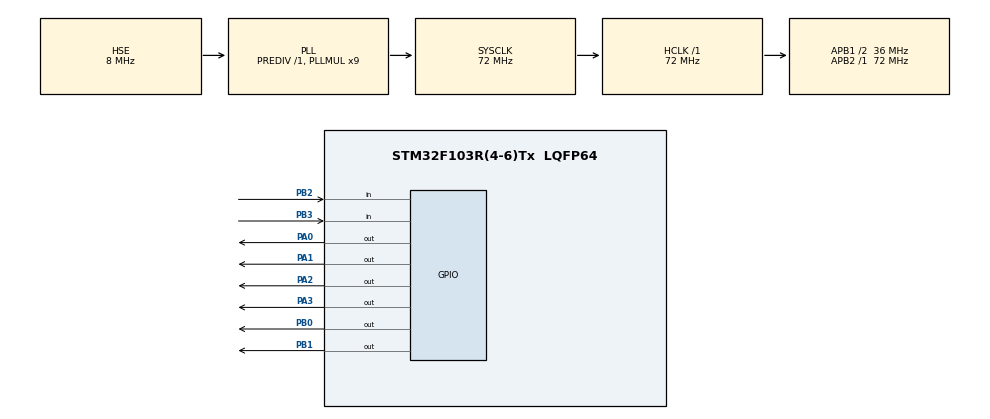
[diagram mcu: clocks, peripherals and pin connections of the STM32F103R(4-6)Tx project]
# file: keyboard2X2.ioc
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Mcu.Family=STM32F1
Mcu.Name=STM32F103R(4-6)Tx
Mcu.Package=LQFP64
NVIC.PriorityGroup=NVIC_PRIORITYGROUP_4
PA0-WKUP.Signal=GPIO_Output
PA1.Signal=GPIO_Output
PA2.Signal=GPIO_Output
PA3.Signal=GPIO_Output
PB0.Signal=GPIO_Output
PB1.Signal=GPIO_Output
PB2.GPIO_PuPd=GPIO_NOPULL
PB2.Signal=GPIO_Input
PB3.GPIO_PuPd=GPIO_NOPULL
PB3.Signal=GPIO_Input
PD0-OSC_IN.Mode=HSE-External-Oscillator
PD0-OSC_IN.Signal=RCC_OSC_IN
PD1-OSC_OUT.Mode=HSE-External-Oscillator
PD1-OSC_OUT.Signal=RCC_OSC_OUT
ProjectManager.HeapSize=0x200
ProjectManager.StackSize=0x400
ProjectManager.TargetToolchain=MDK-ARM V5
RCC.AHBFreq_Value=72000000
RCC.APB1CLKDivider=RCC_HCLK_DIV2
RCC.APB1Freq_Value=36000000
RCC.APB1TimFreq_Value=72000000
RCC.APB2Freq_Value=72000000
RCC.APB2TimFreq_Value=72000000
RCC.HCLKFreq_Value=72000000
RCC.PLLMUL=RCC_PLL_MUL9
RCC.PLLSourceVirtual=RCC_PLLSOURCE_HSE
RCC.SYSCLKFreq_VALUE=72000000
RCC.SYSCLKSource=RCC_SYSCLKSOURCE_PLLCLK
RCC.USBFreq_Value=72000000
VP_SYS_VS_ND.Mode=No_Debug
board=custom

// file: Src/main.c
/* USER CODE BEGIN Header */
/**
  ******************************************************************************
  * @file           : main.c
  * @brief          : Main program body
  ******************************************************************************
  * @attention
  *
  * <h2><center>&copy; Copyright (c) 2021 STMicroelectronics.
  * All rights reserved.</center></h2>
  *
  * This software component is licensed by ST under BSD 3-Clause license,
  * the "License"; You may not use this file except in compliance with the
  * License. You may obtain a copy of the License at:
  *                        opensource.org/licenses/BSD-3-Clause
  *
  ******************************************************************************
  */
/*
@file	《嵌入式微控制器原理及设计》书籍（作者:毕盛等 Email:picy@scut.edu.cn  电子工业出版社）配套实例ch5.6
*/
/* USER CODE END Header */

#include "main.h"
#include "gpio.h"

void SystemClock_Config(void);

int main(void)
{

  /* MCU Configuration--------------------------------------------------------*/

  /* Reset of all peripherals, Initializes the Flash interface and the Systick. */
  HAL_Init();

  /* Configure the system clock */
  SystemClock_Config();

  /* Initialize all configured peripherals */
  MX_GPIO_Init();
  /* USER CODE BEGIN 2 */
  //关闭4盏LED灯
	HAL_GPIO_WritePin(GPIOA,GPIO_PIN_0|GPIO_PIN_1|GPIO_PIN_2|GPIO_PIN_3,GPIO_PIN_SET);
  /* USER CODE END 2 */

  /* Infinite loop */
  while (1)
  {
    HAL_GPIO_WritePin(GPIOB,GPIO_PIN_0,GPIO_PIN_SET);					  //将第一行设置为高电平，进行第一行检测
	  HAL_GPIO_WritePin(GPIOB,GPIO_PIN_1,GPIO_PIN_RESET);					//将第二行设置为低电平，停止第二行的检测
		HAL_Delay(10);
		if(HAL_GPIO_ReadPin(GPIOB,GPIO_PIN_2)){	//检测第一列，如果为高电平，表示按键按下
			HAL_GPIO_WritePin(GPIOA,GPIO_PIN_0,GPIO_PIN_RESET);			//点亮LED
		}else{
			HAL_GPIO_WritePin(GPIOA,GPIO_PIN_0,GPIO_PIN_SET);					//熄灭LED
		}
		if(HAL_GPIO_ReadPin(GPIOB,GPIO_PIN_3)){	//检测第二列，如果为高电平，表示按键按下
			HAL_GPIO_WritePin(GPIOA,GPIO_PIN_1,GPIO_PIN_RESET);				//点亮LED
		}else{
			HAL_GPIO_WritePin(GPIOA,GPIO_PIN_1,GPIO_PIN_SET);					//熄灭LED
		}
		HAL_Delay(10);

		HAL_GPIO_WritePin(GPIOB,GPIO_PIN_0,GPIO_PIN_RESET);				//将第一行设置为低电平，停止第一行的检测
		HAL_GPIO_WritePin(GPIOB,GPIO_PIN_1,GPIO_PIN_SET);					//将第二行设置为高电平，进行第二行检测
		HAL_Delay(10);
		if(HAL_GPIO_ReadPin(GPIOB,GPIO_PIN_2)){	//检测第一列，如果为高电平，表示按键按下
			HAL_GPIO_WritePin(GPIOA,GPIO_PIN_2,GPIO_PIN_RESET);			//点亮LED
		}else{
			HAL_GPIO_WritePin(GPIOA,GPIO_PIN_2,GPIO_PIN_SET);					//熄灭LED
		}
		if(HAL_GPIO_ReadPin(GPIOB,GPIO_PIN_3)){	//检测第二列，如果为高电平，表示按键按下
			HAL_GPIO_WritePin(GPIOA,GPIO_PIN_3,GPIO_PIN_RESET);			//点亮LED
		}else{
			HAL_GPIO_WritePin(GPIOA,GPIO_PIN_3,GPIO_PIN_SET);					//熄灭LED
		}
		HAL_Delay(10);
		//HAL_GPIO_WritePin(GPIOB,GPIO_PIN_1,GPIO_PIN_RESET);				//将第二行设置为低电平，停止第二行的检测 */

  }
}

void SystemClock_Config(void)
{
  RCC_OscInitTypeDef RCC_OscInitStruct = {0};
  RCC_ClkInitTypeDef RCC_ClkInitStruct = {0};

  /** Initializes the CPU, AHB and APB busses clocks
  */
  RCC_OscInitStruct.OscillatorType = RCC_OSCILLATORTYPE_HSE;
  RCC_OscInitStruct.HSEState = RCC_HSE_ON;
  RCC_OscInitStruct.HSEPredivValue = RCC_HSE_PREDIV_DIV1;
  RCC_OscInitStruct.HSIState = RCC_HSI_ON;
  RCC_OscInitStruct.PLL.PLLState = RCC_PLL_ON;
  RCC_OscInitStruct.PLL.PLLSource = RCC_PLLSOURCE_HSE;
  RCC_OscInitStruct.PLL.PLLMUL = RCC_PLL_MUL9;
  if (HAL_RCC_OscConfig(&RCC_OscInitStruct) != HAL_OK)
  {
    Error_Handler();
  }
  /** Initializes the CPU, AHB and APB busses clocks
  */
  RCC_ClkInitStruct.ClockType = RCC_CLOCKTYPE_HCLK|RCC_CLOCKTYPE_SYSCLK
                              |RCC_CLOCKTYPE_PCLK1|RCC_CLOCKTYPE_PCLK2;
  RCC_ClkInitStruct.SYSCLKSource = RCC_SYSCLKSOURCE_PLLCLK;
  RCC_ClkInitStruct.AHBCLKDivider = RCC_SYSCLK_DIV1;
  RCC_ClkInitStruct.APB1CLKDivider = RCC_HCLK_DIV2;
  RCC_ClkInitStruct.APB2CLKDivider = RCC_HCLK_DIV1;

  if (HAL_RCC_ClockConfig(&RCC_ClkInitStruct, FLASH_LATENCY_2) != HAL_OK)
  {
    Error_Handler();
  }
}

void Error_Handler(void)
{
}

/************************ (C) COPYRIGHT STMicroelectronics *****END OF FILE****/
